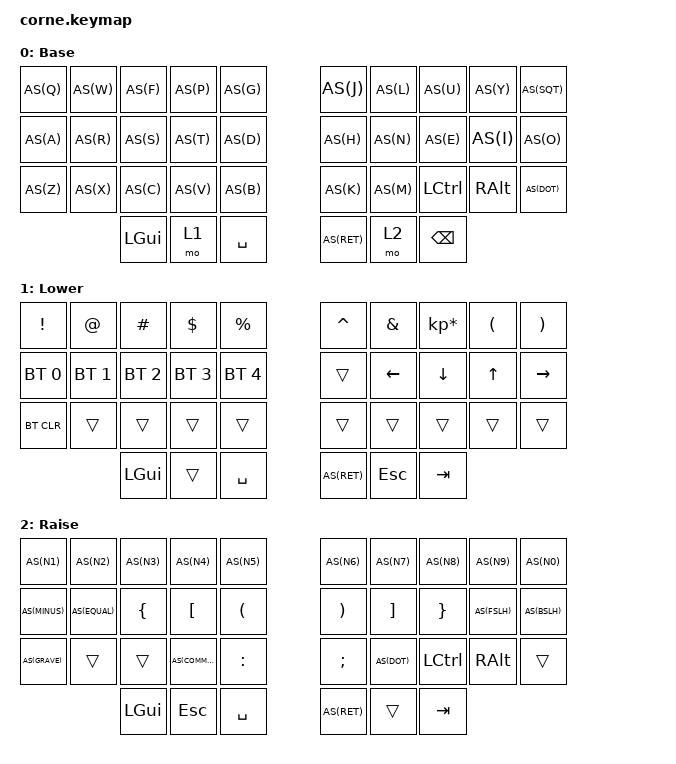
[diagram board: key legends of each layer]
/*
 * Copyright (c) 2020 The ZMK Contributors
 *
 * SPDX-License-Identifier: MIT
 */

#include <behaviors.dtsi>
#include <dt-bindings/zmk/keys.h>
#include <dt-bindings/zmk/bt.h>


#define AS(keycode) &as LS(keycode) keycode

/ {
    chosen {
        zmk,physical-layout = &foostan_corne_5col_layout;
    };

    behaviors {
        as: auto_shift {
            compatible = "zmk,behavior-hold-tap";
            #binding-cells = <2>;
            tapping_term_ms = <300>;
            quick_tap_ms = <0>;
            flavor = "tap-preferred";
            bindings = <&kp>, <&kp>;
        };
    };
        keymap {
                compatible = "zmk,keymap";

                default_layer {
// -----------------------------------------------------------------------------------------
// |  Q  |  W  |  F  |  P  |  G  |     |  J  |  L   |  U   |  Y   | ' |
// |  A  |  R  |  S  |  T  |  D  |     |  H  |  N   |  E   |  I   | O | 
// |  Z  |  X  |  C  |  V  |  B  |     |  K  |  M   | CTRL | OPT  | . |
//             | GUI | LWR | SPC |     | ENT | RSE  | BSPC |
                        display-name = "Base";
                        bindings = <
        AS(Q) AS(W) AS(F) AS(P) AS(G)     AS(J) AS(L) AS(U) AS(Y) AS(SQT)
        AS(A) AS(R) AS(S) AS(T) AS(D)     AS(H) AS(N) AS(E) AS(I) AS(O)
        AS(Z) AS(X) AS(C) AS(V) AS(B)     AS(K) AS(M) &kp LCTL &kp RALT AS(DOT)
        &kp LGUI &mo 1 &kp SPACE     AS(RET) &mo 2  &kp BSPC
                        >;
                };

                lower_layer {
// -----------------------------------------------------------------------------------------
// | !     |  @  |  #  |  $  |  %  |     |  ^  |  &  |  *  |  (  |  )  |
// | BT1   | BT2 | BT3 | BT4 | BT5 |     | LFT | DWN |  UP | RGT |     |
// | BTCLR |     |     |     |     |     |     |     |     |     |     |
//               | GUI |     | SPC |     | ENT | ESC | TAB |
                        display-name = "Lower";
                        bindings = <
   &kp EXCL     &kp AT       &kp HASH     &kp DLLR     &kp PRCNT        &kp CARET &kp AMPS  &kp KP_MULTIPLY &kp LPAR  &kp RPAR
   &bt BT_SEL 0 &bt BT_SEL 1 &bt BT_SEL 2 &bt BT_SEL 3 &bt BT_SEL 4     &trans    &kp LEFT  &kp DOWN        &kp UP    &kp RIGHT  
   &bt BT_CLR   &trans       &trans       &trans       &trans           &trans    &trans    &trans          &trans    &trans 
                             &kp LGUI     &trans       &kp SPACE        AS(RET)   &kp ESC   &kp TAB
                        >;
                };

                raise_layer {
// -----------------------------------------------------------------------------------------
// | 1! |  2@ |  3# |  4$ |  5% |     |  6^ |  7& |  8* |  9(  |  0)  |
// | -_ |  =+ |  {  |  [  |  (  |     |  )  |  ]  |  }  |  /?  |  \|  |
// | `~ |     |     |  ,< |  :  |     |  ;  |  .> | CTRL| META |      |
//            | GUI | ESC | SPC |     | ENT |     | TAB |
                        display-name = "Raise";
                        bindings = <

   AS(N1)    AS(N2)    AS(N3)    AS(N4)    AS(N5)        AS(N6)    AS(N7)    AS(N8)    AS(N9)   AS(N0)
   AS(MINUS) AS(EQUAL) &kp LBRC  &kp LBKT  &kp LPAR      &kp RPAR  &kp RBKT  &kp RBRC  AS(FSLH) AS(BSLH)
   AS(GRAVE) &trans    &trans    AS(COMMA) &kp COLON     &kp SEMI  AS(DOT)   &kp LCTRL &kp RALT &trans
                       &kp LGUI  &kp ESC   &kp SPACE     AS(RET)   &trans    &kp TAB
                        >;
                };

                extra_1 {
                        status = "reserved";
                };

                extra_2 {
                        status = "reserved";
                };

                extra_3 {
                        status = "reserved";
                };
        };
};
